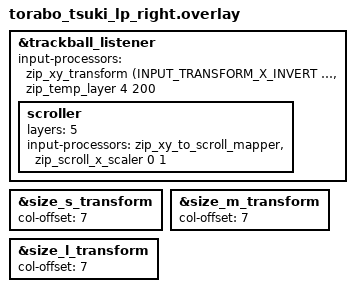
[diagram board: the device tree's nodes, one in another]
#include "torabo_tsuki_lp.dtsi"
#include <input/processors.dtsi>
#include <dt-bindings/zmk/input_transform.h>
#include <zephyr/dt-bindings/input/input-event-codes.h>

&trackball_listener {
    input-processors = <
		&zip_xy_transform (INPUT_TRANSFORM_X_INVERT | INPUT_TRANSFORM_Y_INVERT)
		&zip_temp_layer 4 200
	>;

	scroller {
		layers = <5>;
		input-processors = <
			&zip_xy_to_scroll_mapper
			&zip_scroll_x_scaler 0 1
		>;
	};
};

&size_s_transform {
    col-offset = <7>;
};

&size_m_transform {
    col-offset = <7>;
};

&size_l_transform {
    col-offset = <7>;
};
